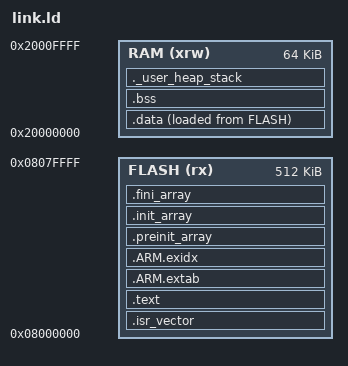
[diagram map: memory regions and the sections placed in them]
ENTRY(Reset_Handler)

MEMORY
{
    FLASH (rx)  : ORIGIN = 0x08000000, LENGTH = 512K
    RAM   (xrw) : ORIGIN = 0x20000000, LENGTH = 64K
}

_estack = ORIGIN(RAM) + LENGTH(RAM);
_Min_Heap_Size = 0;
_Min_Stack_Size = 0x400;

SECTIONS
{
    .isr_vector :
    {
        . = ALIGN(4);
        KEEP(*(.isr_vector))
        . = ALIGN(4);
    } > FLASH

    .text :
    {
        . = ALIGN(4);
        *(.text*)
        *(.rodata*)
        *(.glue_7)
        *(.glue_7t)
        KEEP(*(.init))
        KEEP(*(.fini))
        . = ALIGN(4);
        _etext = .;
    } > FLASH

    .ARM.extab :
    {
        *(.ARM.extab* .gnu.linkonce.armextab.*)
    } > FLASH

    .ARM.exidx :
    {
        __exidx_start = .;
        *(.ARM.exidx* .gnu.linkonce.armexidx.*)
        __exidx_end = .;
    } > FLASH

    .preinit_array :
    {
        PROVIDE_HIDDEN(__preinit_array_start = .);
        KEEP(*(.preinit_array*))
        PROVIDE_HIDDEN(__preinit_array_end = .);
    } > FLASH

    .init_array :
    {
        PROVIDE_HIDDEN(__init_array_start = .);
        KEEP(*(SORT(.init_array.*)))
        KEEP(*(.init_array*))
        PROVIDE_HIDDEN(__init_array_end = .);
    } > FLASH

    .fini_array :
    {
        PROVIDE_HIDDEN(__fini_array_start = .);
        KEEP(*(SORT(.fini_array.*)))
        KEEP(*(.fini_array*))
        PROVIDE_HIDDEN(__fini_array_end = .);
    } > FLASH

    .data :
    {
        . = ALIGN(4);
        _sdata = .;
        *(.data*)
        . = ALIGN(4);
        _edata = .;
    } > RAM AT > FLASH

    /* Reset_Handler copies this range from Flash before calling main(). */
    _sidata = LOADADDR(.data);

    .bss (NOLOAD) :
    {
        . = ALIGN(4);
        _sbss = .;
        *(.bss*)
        *(COMMON)
        . = ALIGN(4);
        _ebss = .;
    } > RAM

    ._user_heap_stack (NOLOAD) :
    {
        . = ALIGN(8);
        _end = .;
        end = .;
        . = . + _Min_Heap_Size;
        . = . + _Min_Stack_Size;
        . = ALIGN(8);
    } > RAM

    ASSERT(_estack >= ., "ZET6 RAM overflow: enlarge nothing; reduce RAM use")
}
